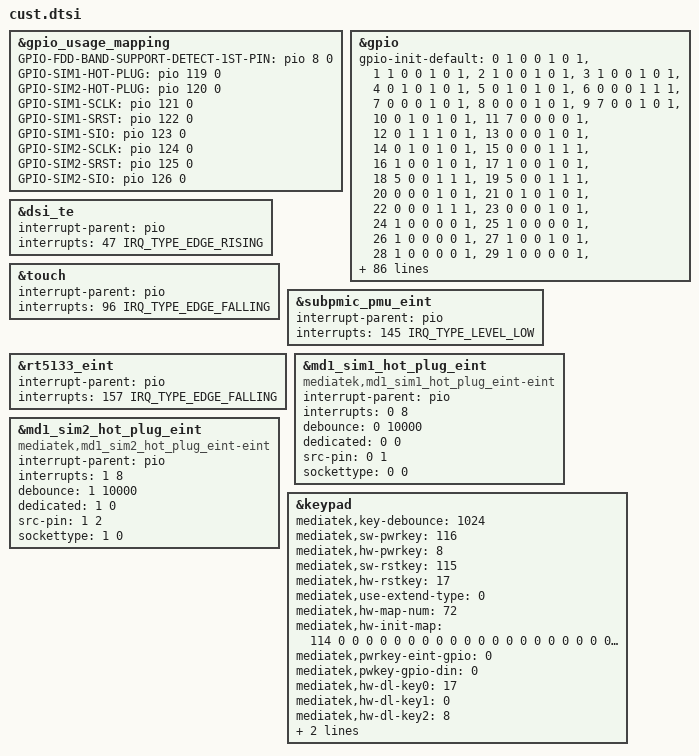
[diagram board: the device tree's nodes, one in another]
/*
 * Generated by MTK SP DrvGen Version: 3.5.160809 for MT6886.
 * 2024-03-22 10:16:33
 * Do Not Modify The File.
 * Copyright Mediatek Inc. (c) 2016.
 */

/*************************
 * ADC DTSI File
 ************************/



/*************************
 * CLK_BUF DTSI File
 ************************/



/*************************
 * I2C DTSI File
 ************************/



/*************************
 * GPIO DTSI File
 ************************/

&gpio_usage_mapping {
	GPIO-FDD-BAND-SUPPORT-DETECT-1ST-PIN = <&pio 8 0>;
	GPIO-SIM1-HOT-PLUG = <&pio 119 0>;
	GPIO-SIM2-HOT-PLUG = <&pio 120 0>;
	GPIO-SIM1-SCLK = <&pio 121 0>;
	GPIO-SIM1-SRST = <&pio 122 0>;
	GPIO-SIM1-SIO = <&pio 123 0>;
	GPIO-SIM2-SCLK = <&pio 124 0>;
	GPIO-SIM2-SRST = <&pio 125 0>;
	GPIO-SIM2-SIO = <&pio 126 0>;
};

&gpio{
	gpio-init-default = <0 1 0 0 1 0 1>,
		<1 1 0 0 1 0 1>,
		<2 1 0 0 1 0 1>,
		<3 1 0 0 1 0 1>,
		<4 0 1 0 1 0 1>,
		<5 0 1 0 1 0 1>,
		<6 0 0 0 1 1 1>,
		<7 0 0 0 1 0 1>,
		<8 0 0 0 1 0 1>,
		<9 7 0 0 1 0 1>,
		<10 0 1 0 1 0 1>,
		<11 7 0 0 0 0 1>,
		<12 0 1 1 1 0 1>,
		<13 0 0 0 1 0 1>,
		<14 0 1 0 1 0 1>,
		<15 0 0 0 1 1 1>,
		<16 1 0 0 1 0 1>,
		<17 1 0 0 1 0 1>,
		<18 5 0 0 1 1 1>,
		<19 5 0 0 1 1 1>,
		<20 0 0 0 1 0 1>,
		<21 0 1 0 1 0 1>,
		<22 0 0 0 1 1 1>,
		<23 0 0 0 1 0 1>,
		<24 1 0 0 0 0 1>,
		<25 1 0 0 0 0 1>,
		<26 1 0 0 0 0 1>,
		<27 1 0 0 1 0 1>,
		<28 1 0 0 0 0 1>,
		<29 1 0 0 0 0 1>,
		<30 1 0 0 0 0 1>,
		<31 1 0 0 0 0 1>,
		<32 1 0 0 0 0 1>,
		<33 1 0 0 0 0 1>,
		<34 1 0 0 0 0 1>,
		<35 1 0 0 0 0 1>,
		<36 1 0 0 0 0 1>,
		<37 1 0 0 0 0 1>,
		<38 1 0 0 0 0 1>,
		<39 1 0 0 0 0 1>,
		<40 1 0 0 1 0 1>,
		<41 1 0 0 1 0 1>,
		<42 1 0 0 1 0 1>,
		<43 2 0 0 1 1 1>,
		<44 2 0 0 1 1 1>,
		<45 2 0 0 1 1 1>,
		<46 2 0 0 1 1 1>,
		<47 1 0 0 1 0 1>,
		<48 0 1 0 1 0 1>,
		<49 1 0 0 1 1 1>,
		<50 1 0 0 1 1 1>,
		<51 1 0 0 1 1 1>,
		<52 1 0 0 1 1 1>,
		<54 1 0 0 0 0 0>,
		<55 1 0 0 1 0 0>,
		<56 1 0 0 0 0 0>,
		<57 1 0 0 1 0 0>,
		<58 1 0 0 0 0 0>,
		<59 1 0 0 1 0 0>,
		<60 1 0 0 1 0 0>,
		<61 1 0 0 1 0 0>,
		<62 1 0 0 1 0 1>,
		<63 1 0 0 1 0 1>,
		<64 1 0 0 1 0 1>,
		<65 1 0 0 1 0 1>,
		<66 1 0 0 0 0 1>,
		<67 0 0 0 1 0 1>,
		<68 0 0 0 1 0 1>,
		<69 0 0 0 1 0 1>,
		<70 0 0 0 1 0 0>,
		<71 0 0 0 1 0 1>,
		<72 0 0 0 1 0 1>,
		<73 0 0 0 1 0 0>,
		<74 0 0 0 1 0 1>,
		<75 0 0 0 1 0 1>,
		<76 0 0 0 1 0 1>,
		<77 0 0 0 1 0 1>,
		<78 0 0 0 1 0 1>,
		<79 0 0 0 1 0 1>,
		<80 0 0 0 1 0 1>,
		<81 0 0 0 1 0 1>,
		<82 0 0 0 1 0 1>,
		<83 0 0 0 1 0 1>,
		<84 0 0 0 1 0 1>,
		<85 0 0 0 1 0 1>,
		<86 0 0 0 1 0 0>,
		<87 0 0 0 1 0 0>,
		<88 0 1 0 1 0 1>,
		<89 0 1 0 1 0 1>,
		<90 0 1 0 1 0 1>,
		<91 0 1 0 1 0 0>,
		<92 0 1 1 1 0 1>,
		<93 0 0 0 1 0 1>,
		<94 0 1 0 1 0 1>,
		<95 0 0 0 1 0 1>,
		<96 0 0 0 0 0 1>,
		<97 1 0 0 0 0 1>,
		<98 1 0 0 1 1 1>,
		<99 0 0 0 1 0 1>,
		<100 0 0 0 1 0 1>,
		<101 0 0 0 1 0 1>,
		<102 1 0 0 1 0 1>,
		<103 1 0 0 1 0 1>,
		<104 1 0 0 1 1 1>,
		<105 1 0 0 1 0 1>,
		<106 2 0 0 1 1 1>,
		<107 2 0 0 1 0 1>,
		<108 2 0 0 1 0 1>,
		<109 2 0 0 1 1 1>,
		<110 1 0 0 1 0 1>,
		<111 1 0 0 1 1 1>,
		<112 1 0 0 1 0 1>,
		<113 1 0 0 1 0 1>,
		<114 0 0 0 1 0 1>,
		<115 0 0 0 1 0 1>,
		<116 1 0 0 1 0 1>,
		<117 1 0 0 1 0 1>,
		<118 0 0 0 1 0 1>,
		<119 1 0 0 1 1 1>,
		<120 1 0 0 1 1 1>,
		<121 1 0 0 0 0 1>,
		<122 1 0 0 0 0 1>,
		<123 1 0 0 1 1 1>,
		<124 1 0 0 0 0 1>,
		<125 1 0 0 0 0 1>,
		<126 1 0 0 1 1 1>,
		<127 0 0 0 1 0 1>,
		<128 0 0 0 1 0 1>,
		<129 0 0 0 1 0 1>,
		<130 0 0 0 1 0 1>,
		<131 0 0 0 1 0 1>,
		<132 0 0 0 1 0 1>,
		<133 3 0 0 1 0 1>,
		<134 1 0 0 1 1 1>,
		<135 0 0 0 1 0 1>,
		<136 7 0 0 1 0 1>,
		<137 1 0 0 1 0 1>,
		<138 1 0 0 1 1 1>,
		<139 1 0 0 1 0 1>,
		<140 1 0 0 1 0 1>,
		<141 0 0 0 1 0 1>,
		<142 0 0 0 1 0 1>,
		<143 0 0 0 1 0 1>,
		<144 0 0 0 1 0 1>,
		<145 0 0 0 1 1 1>,
		<146 0 1 0 1 0 1>,
		<147 0 1 0 1 0 1>,
		<148 0 1 0 1 0 1>,
		<149 0 1 0 1 0 1>,
		<150 1 0 0 1 1 1>,
		<151 1 0 0 1 1 1>,
		<152 1 0 0 1 1 1>,
		<153 1 0 0 1 1 1>,
		<154 1 0 0 1 1 1>,
		<155 1 0 0 1 1 1>,
		<156 0 1 0 1 0 1>,
		<157 0 0 0 1 1 1>,
		<158 0 0 0 1 0 1>,
		<159 0 0 0 1 0 1>,
		<160 0 1 0 1 0 1>,
		<161 0 1 0 1 0 1>,
		<162 0 1 0 1 0 1>,
		<163 0 1 0 1 0 1>,
		<164 0 1 0 1 0 1>,
		<165 0 0 0 1 0 1>,
		<166 0 0 0 1 0 1>,
		<167 0 0 0 1 0 1>,
		<168 0 0 0 1 0 1>,
		<169 1 0 0 1 0 1>,
		<170 1 0 0 1 0 1>,
		<171 0 0 0 1 0 1>,
		<172 1 0 0 1 0 1>,
		<173 0 0 0 1 0 1>,
		<174 1 0 0 1 1 1>,
		<175 1 0 0 1 1 1>,
		<176 1 0 0 1 1 1>,
		<177 1 0 0 1 1 1>,
		<178 1 0 0 1 1 1>,
		<179 1 0 0 1 1 1>,
		<180 0 0 0 1 0 1>,
		<181 0 0 0 1 0 1>,
		<182 0 1 0 1 0 1>,
		<183 0 0 0 1 0 1>,
		<184 0 0 0 1 0 1>,
		<185 0 0 0 1 0 0>,
		<186 0 0 0 1 0 1>,
		<187 0 0 0 1 0 0>,
		<188 0 0 0 1 0 1>,
		<189 0 0 0 1 0 1>,
		<190 0 0 0 1 0 0>,
		<191 0 0 0 1 0 0>,
		<192 0 0 0 1 0 1>,
		<193 0 0 0 1 0 1>,
		<194 0 0 0 1 0 1>,
		<195 0 0 0 1 0 1>,
		<196 0 0 0 1 0 1>,
		<197 0 0 0 1 0 1>,
		<198 0 0 0 1 0 1>,
		<199 0 0 0 1 0 1>,
		<200 0 0 0 1 0 1>,
		<201 0 0 0 1 0 1>,
		<202 0 0 0 1 0 1>;
};


/*************************
 * EINT DTSI File
 ************************/

#include <dt-bindings/interrupt-controller/irq.h>
#include <dt-bindings/interrupt-controller/arm-gic.h>

&dsi_te {
	interrupt-parent = <&pio>;
	interrupts = <47 IRQ_TYPE_EDGE_RISING>;
	status = "okay";
};

&touch {
	interrupt-parent = <&pio>;
	interrupts = <96 IRQ_TYPE_EDGE_FALLING>;
	status = "okay";
};

&subpmic_pmu_eint {
	interrupt-parent = <&pio>;
	interrupts = <145 IRQ_TYPE_LEVEL_LOW>;
	status = "okay";
};

&rt5133_eint {
	interrupt-parent = <&pio>;
	interrupts = <157 IRQ_TYPE_EDGE_FALLING>;
	status = "okay";
};



/*************************
 * MD1_EINT DTSI File
 ************************/

&md1_sim1_hot_plug_eint {
	compatible = "mediatek,md1_sim1_hot_plug_eint-eint";
	interrupt-parent = <&pio>;
	interrupts = <0 8>;
	debounce = <0 10000>;
	dedicated = <0 0>;
	src-pin = <0 1>;
	sockettype = <0 0>;
	status = "okay";
};

&md1_sim2_hot_plug_eint {
	compatible = "mediatek,md1_sim2_hot_plug_eint-eint";
	interrupt-parent = <&pio>;
	interrupts = <1 8>;
	debounce = <1 10000>;
	dedicated = <1 0>;
	src-pin = <1 2>;
	sockettype = <1 0>;
	status = "okay";
};



/*************************
 * PMIC DTSI File
 ************************/



/*************************
 * POWER DTSI File
 ************************/



/*************************
 * KPD DTSI File
 ************************/

&keypad {
	mediatek,key-debounce = <1024>;
	mediatek,sw-pwrkey = <116>;
	mediatek,hw-pwrkey = <8>;
	mediatek,sw-rstkey  = <115>;
	mediatek,hw-rstkey = <17>;
	mediatek,use-extend-type = <0>;
	/*HW Keycode [0~71] -> Linux Keycode*/
	mediatek,hw-map-num = <72>;
	mediatek,hw-init-map = <114 0 0 0 0 0 0 0 0 0 0 0 0 0 0 0 0 0 0 0 0 0 0 0
				0 0 0 0 0 0 0 0 0 0 0 0 0 0 0 0 0 0 0 0 0 0 0 0
				0 0 0 0 0 0 0 0 0 0 0 0 0 0 0 0 0 0 0 0 0 0 0 0>;
	mediatek,pwrkey-eint-gpio = <0>;
	mediatek,pwkey-gpio-din  = <0>;
	mediatek,hw-dl-key0 = <17>;
	mediatek,hw-dl-key1 = <0>;
	mediatek,hw-dl-key2 = <8>;
	mediatek,hw-recovery-key = <17>;
	mediatek,hw-factory-key = <0>;
	status = "okay";
};


